# M030GAE register map
File version: 1.0
Registers are 32-bit, read-write, reset 0x0 unless marked. A register's access mark holds for its fields unless they carry their own. Offsets are from the block's base; [hi:lo] are bit positions; {n}, {i} and the like mark numbered series; 'fields as' and 'values as' point back to an identical list.

## I2C0 — I2C Register Map
Base 0x40080000
Same registers: I2C1 0x40081000
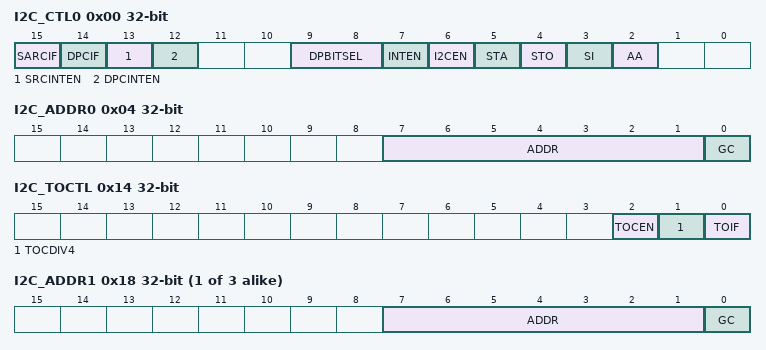
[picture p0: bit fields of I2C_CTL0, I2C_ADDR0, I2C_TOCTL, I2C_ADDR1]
0x00 I2C_CTL0 — I2C Control Register 0
  [15] SARCIF — Slave Address Read Command Interrupt Flag. This bit is set by hardware when I2C receive address is matched with read command. Note: This bit is cleared by writing 1 to it.
  [14] DPCIF — Data Phase Count Interrupt Flag. This bit is set by hardware when I2C transfer bit count is equal to DPBITSEL setting. Note: This bit is cleared by writing 1 to it.
  [13] SRCINTEN — Slave Read Command Interrupt Enable Bit
    0=Slave Read Command Interrupt Disabled; 1=Slave Read Command Interrupt Enabled
  [12] DPCINTEN — Data Phase Count Interrupt Enable Bit
    0=Data Phase Count Interrupt Disabled; 1=Data Phase Count Interrupt Enabled
  [9:8] DPBITSEL — Data Phase Bit Count Select
    0=DPCIF never set by hardware; 1=When I2C is transfer data and bit count equal to 6, DPCIF will be set by hardware; 2=When I2C is transfer data and bit count equal to 7, DPCIF will be set by hardware; 3=When I2C is transfer data and bit count equal to 8, DPCIF will be set by hardware
  [7] INTEN — Enable Interrupt
    0=I2C interrupt Disabled; 1=I2C interrupt Enabled
  [6] I2CEN — I2C Controller Enable Bit
    0=I2C controller Disabled; 1=I2C controller Enabled
  [5] STA — I2C START Control. Setting STA to logic 1 will enter Master mode, and the I2C hardware sends a START or repeat START condition to bus when the bus is free.
  [4] STO — I2C STOP Control. In Master mode, setting STO will transmit a STOP condition to bus and then I2C controller will check the bus condition if a STOP condition is detected. This bit will be cleared by hardware automatically.
  [3] SI — I2C Interrupt Flag. When a new I2C state is present in the I2C_STATUS0 register, the SI flag is set by hardware. If bit INTEN (I2C_CTL0 [7]) is set, the I2C interrupt is requested. SI must be cleared by software. Clear SI by writing 1 to this bit.
  [2] AA — Assert Acknowledge Control
0x04 I2C_ADDR0 — I2C Slave Address Register0
  [7:1] ADDR — I2C Address. The content of this register is irrelevant when I2C is in Master mode. In the slave mode, the seven most significant bits must be loaded with the chip's own address. The I2C hardware will react if either of the address is matched. Note: When software set 7'h00, the address cannot be used.
  [0] GC — General Call Function
    0=General Call Function Disabled; 1=General Call Function Enabled
0x08 I2C_DAT — I2C Data Register
  [7:0] DAT — I2C Data. Bit [7:0] is located with the 8-bit transferred/received data of I2C serial port.
0x0C I2C_STATUS0 ro reset 0xF8 — I2C Status Register 0
  [7:0] STATUS — I2C Status
0x10 I2C_CLKDIV — I2C Clock Divided Register
  [9:0] DIVIDER — I2C Clock Divided. Note: The minimum value of I2C_CLKDIV is 4.
0x14 I2C_TOCTL — I2C Time-out Control Register
  [2] TOCEN — Time-out Counter Enable Bit. When enabled, the 14-bit time-out counter will start counting when SI is cleared. Setting flag SI to '1' will reset counter and re-start up counting after SI is cleared.
    0=Time-out counter Disabled; 1=Time-out counter Enabled
  [1] TOCDIV4 — Time-out Counter Input Clock Divided by 4. When enabled, the time-out period is extended 4 times.
    0=Time-out period is extend 4 times Disabled; 1=Time-out period is extend 4 times Enabled
  [0] TOIF — Time-out Flag. This bit is set by hardware when I2C time-out happened and it can interrupt CPU if I2C interrupt enable bit (INTEN) is set to 1. Note: Software can write 1 to clear this bit.
{0x14+4i} I2C_ADDR{i} (i=1..3) — I2C Slave Address Register{i}
  fields as I2C_ADDR0
{0x24+4i} I2C_ADDRMSK{i} (i=0..3) — I2C Slave Address Mask Register{i}
  [7:1] ADDRMSK — I2C Address Mask. I2C bus controllers support multiple address recognition with four address mask registers. When the bit in the address mask register is set to one, it means the received corresponding address bit is don't-care. If the bit is set to 0, that means the received corresponding register bit should be exactly the same as address register.
    0=Mask Disabled (the received corresponding register bit should be exactly the same as address register.); 1=Mask Enabled (the received corresponding address bit is don't care.)
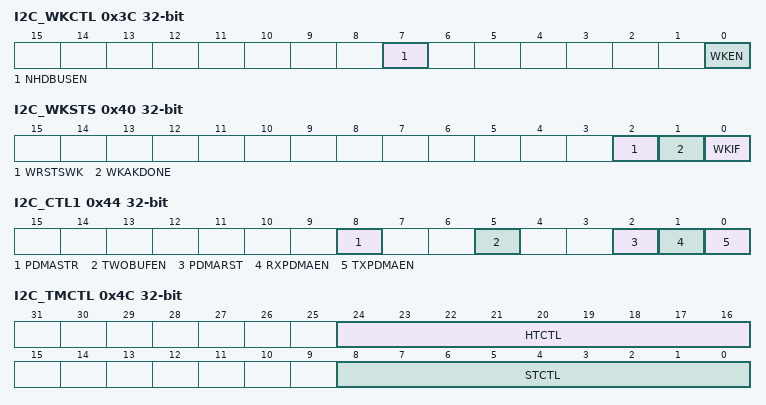
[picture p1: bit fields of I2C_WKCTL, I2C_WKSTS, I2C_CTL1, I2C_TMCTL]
0x3C I2C_WKCTL — I2C Wake-up Control Register
  [7] NHDBUSEN — I2C No Hold BUS Enable Bit. Note: The I2C controller could respond when WKIF event is not cleared. It may cause error data transmitted or received. If data transmitted or received when WKIF event is not cleared, user must reset I2C controller and execute the original operation again.
    0=I2C holds bus after wake-up; 1=I2C does not hold bus after wake-up
  [0] WKEN — I2C Wake-up Enable Bit
    0=I2C wake-up function Disabled; 1=I2C wake-up function Enabled
0x40 I2C_WKSTS — I2C Wake-up Status Register
  [2] WRSTSWK ro — Read/Write Status Bit in Address Wakeup Frame (Read Only). Note: This bit will be cleared when software can write 1 to WKAKDONE (I2C_WKSTS[1]) bit.
    0=Write command be record on the address match wake-up frame; 1=Read command be record on the address match wake-up frame
  [1] WKAKDONE — Wakeup Address Frame Acknowledge Bit Done. Note: This bit cannot release WKIF. Software can write 1 to clear this bit.
    0=The ACK bit cycle of address match frame is not done; 1=The ACK bit cycle of address match frame is done in power-down
  [0] WKIF — I2C Wake-up Flag. When chip is woken up from Power-down mode by I2C, this bit is set to 1. Software can write 1 to clear this bit.
0x44 I2C_CTL1 — I2C Control Register 1
  [8] PDMASTR — PDMA Stretch Bit
    0=I2C send STOP automatically after PDMA transfer done. (Only master TX); 1=I2C SCL bus is stretched by hardware after PDMA transfer done if the SI is not cleared. (Only master TX)
  [5] TWOBUFEN — Two-level BUFFER Enable Bit. Set to enable the two-level buffer for I2C transmitted or received buffer. It is used to improve the performance of the I2C bus. It only support in slave mode.
    0=Two-level buffer Disabled; 1=Two-level buffer Enabled
  [2] PDMARST — PDMA Reset
    0=No effect; 1=Reset the I2C request to PDMA
  [1] RXPDMAEN — PDMA Receive Channel Available
    0=Receive PDMA function Disabled; 1=Receive PDMA function Enabled
  [0] TXPDMAEN — PDMA Transmit Channel Available
    0=Transmit PDMA function Disabled; 1=Transmit PDMA function Enabled
0x48 I2C_STATUS1 — I2C Status Register 1
  [8] ONBUSY ro — On Bus Busy (Read Only). Indicate that a communication is in progress on the bus. It is set by hardware when a START condition is detected. It is cleared by hardware when a STOP condition is detected.
    0=The bus is idle (both SCLK and SDA High); 1=The bus is busy
0x4C I2C_TMCTL — I2C Timing Configure Control Register
  [24:16] HTCTL — Hold Time Configure Control. This field is used to generate the delay timing between SCL falling edge and SDA rising edge in transmission mode.
  [8:0] STCTL — Setup Time Configure Control. This field is used to generate a delay timing between SDA falling edge and SCL rising edge in transmission mode. Note: Setup time setting should not make SCL output less than three PCLKs.
